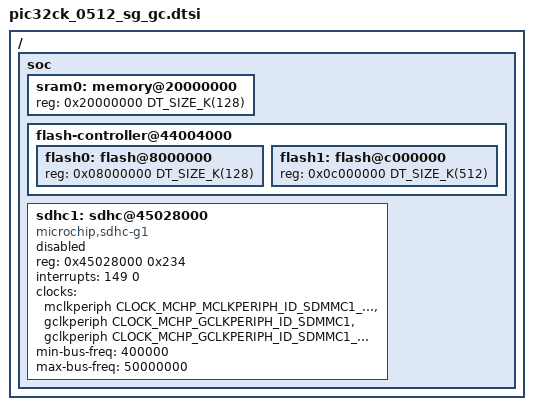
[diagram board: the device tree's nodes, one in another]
/*
 * Copyright (c) 2026 Microchip Technology Inc.
 *
 * SPDX-License-Identifier: Apache-2.0
 */
/ {
	soc {
		sram0: memory@20000000 {
			reg = <0x20000000 DT_SIZE_K(128)>;
		};

		flash-controller@44004000 {
			flash0: flash@8000000 {
				reg = <0x08000000 DT_SIZE_K(128)>;
				ranges = <0x0 0x08000000 DT_SIZE_K(128)>;
			};

			flash1: flash@c000000 {
				reg = <0x0c000000 DT_SIZE_K(512)>;
				ranges = <0x0 0x0c000000 DT_SIZE_K(512)>;
			};
		};

		sdhc1: sdhc@45028000 {
			compatible = "microchip,sdhc-g1";
			reg = <0x45028000 0x234>;
			interrupts = <149 0>;
			clocks = <&mclkperiph CLOCK_MCHP_MCLKPERIPH_ID_SDMMC1_AHB>,
				 <&gclkperiph CLOCK_MCHP_GCLKPERIPH_ID_SDMMC1>,
				 <&gclkperiph CLOCK_MCHP_GCLKPERIPH_ID_SDMMC1_SLOW>;
			clock-names = "mclk", "gclk", "gclk-slow";
			min-bus-freq = <400000>;
			max-bus-freq = <50000000>;
			status = "disabled";
		};
	};
};
